# STM32G0C1VET6 register map
File version: 1.0
Registers are 32-bit, access not given, reset 0x0 unless marked. A register's access mark holds for its fields unless they carry their own. Offsets are from the block's base; [hi:lo] are bit positions; {n}, {i} and the like mark numbered series.

## RCC
Base 0x40021000
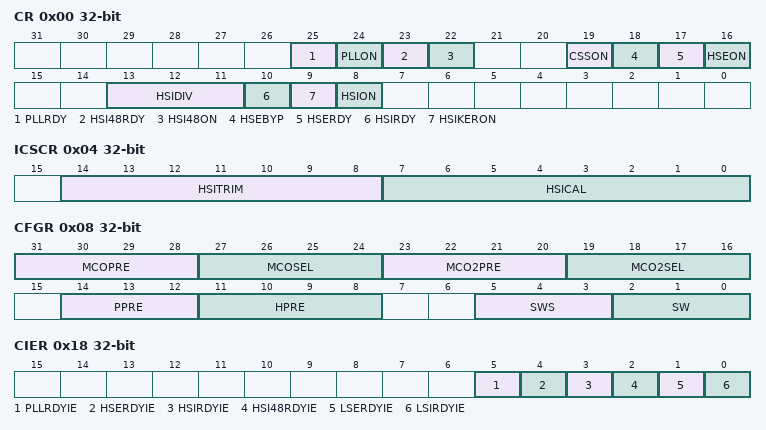
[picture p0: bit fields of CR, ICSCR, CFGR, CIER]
0x00 CR
  [25] PLLRDY, [24] PLLON, [23] HSI48RDY, [22] HSI48ON, [19] CSSON, [18] HSEBYP, [17] HSERDY, [16] HSEON, [13:11] HSIDIV, [10] HSIRDY, [9] HSIKERON, [8] HSION
0x04 ICSCR
  [14:8] HSITRIM, [7:0] HSICAL
0x08 CFGR
  [31:28] MCOPRE, [27:24] MCOSEL, [23:20] MCO2PRE, [19:16] MCO2SEL, [14:12] PPRE, [11:8] HPRE, [5:3] SWS, [2:0] SW
0x0C PLLCFGR
  [31:29] PLLR, [28] PLLREN, [27:25] PLLQ, [24] PLLQEN, [21:17] PLLP, [16] PLLPEN, [14:8] PLLN, [6:4] PLLM, [1] PLLSRC_HSI, [1:0] PLLSRC_HSE
0x14 CRRCR
  [8:0] HSI48CAL
0x18 CIER
  [5] PLLRDYIE, [4] HSERDYIE, [3] HSIRDYIE, [2] HSI48RDYIE, [1] LSERDYIE, [0] LSIRDYIE
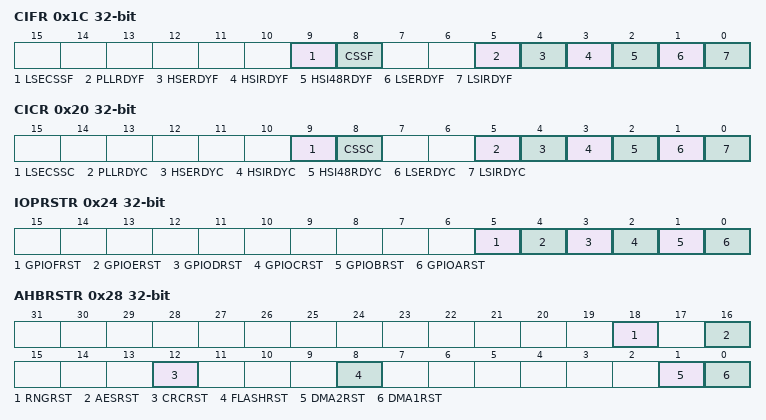
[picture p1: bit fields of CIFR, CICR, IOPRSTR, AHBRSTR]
0x1C CIFR
  [9] LSECSSF, [8] CSSF, [5] PLLRDYF, [4] HSERDYF, [3] HSIRDYF, [2] HSI48RDYF, [1] LSERDYF, [0] LSIRDYF
0x20 CICR
  [9] LSECSSC, [8] CSSC, [5] PLLRDYC, [4] HSERDYC, [3] HSIRDYC, [2] HSI48RDYC, [1] LSERDYC, [0] LSIRDYC
0x24 IOPRSTR
  [5] GPIOFRST, [4] GPIOERST, [3] GPIODRST, [2] GPIOCRST, [1] GPIOBRST, [0] GPIOARST
0x28 AHBRSTR
  [18] RNGRST, [16] AESRST, [12] CRCRST, [8] FLASHRST, [1] DMA2RST, [0] DMA1RST
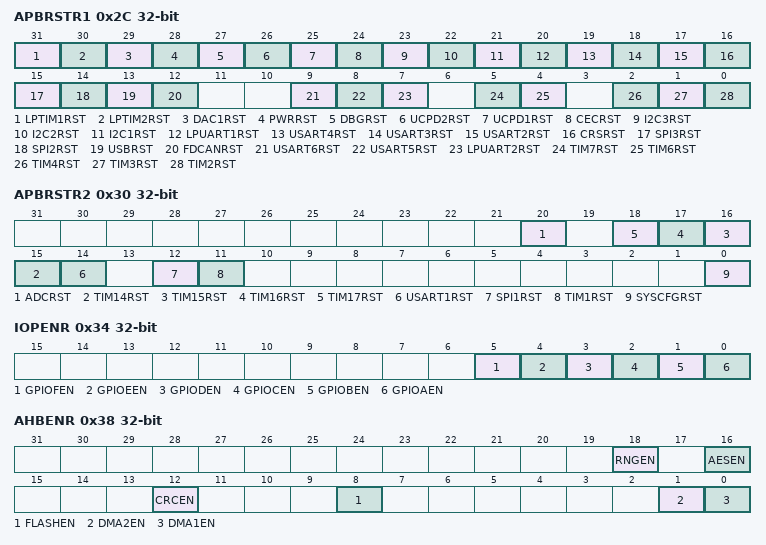
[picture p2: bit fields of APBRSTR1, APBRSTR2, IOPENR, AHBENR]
0x2C APBRSTR1
  [31] LPTIM1RST, [30] LPTIM2RST, [29] DAC1RST, [28] PWRRST, [27] DBGRST, [26] UCPD2RST, [25] UCPD1RST, [24] CECRST, [23] I2C3RST, [22] I2C2RST, [21] I2C1RST, [20] LPUART1RST, [19] USART4RST, [18] USART3RST, [17] USART2RST, [16] CRSRST, [15] SPI3RST, [14] SPI2RST, [13] USBRST, [12] FDCANRST, [9] USART6RST, [8] USART5RST, [7] LPUART2RST, [5] TIM7RST, [4] TIM6RST, [2] TIM4RST, [1] TIM3RST, [0] TIM2RST
0x30 APBRSTR2
  [20] ADCRST, [n+1] TIM{n}RST (n=14..17), [14] USART1RST, [12] SPI1RST, [11] TIM1RST, [0] SYSCFGRST
0x34 IOPENR
  [5] GPIOFEN, [4] GPIOEEN, [3] GPIODEN, [2] GPIOCEN, [1] GPIOBEN, [0] GPIOAEN
0x38 AHBENR
  [18] RNGEN, [16] AESEN, [12] CRCEN, [8] FLASHEN, [1] DMA2EN, [0] DMA1EN
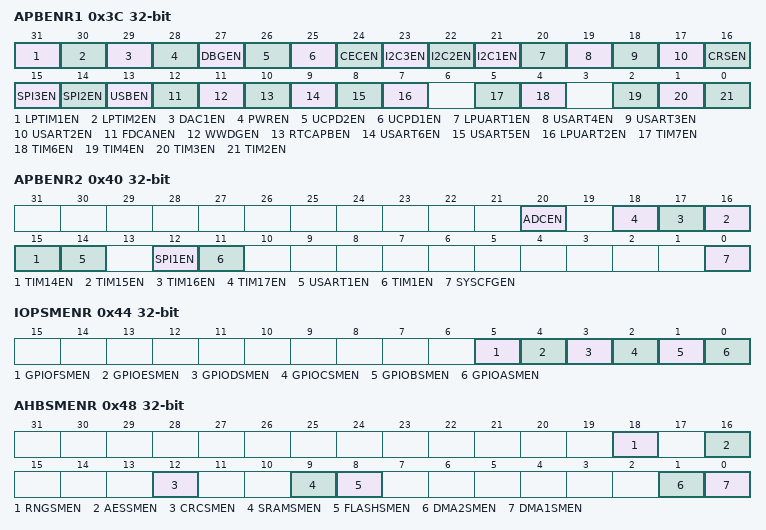
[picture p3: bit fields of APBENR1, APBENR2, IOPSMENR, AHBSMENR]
0x3C APBENR1
  [31] LPTIM1EN, [30] LPTIM2EN, [29] DAC1EN, [28] PWREN, [27] DBGEN, [26] UCPD2EN, [25] UCPD1EN, [24] CECEN, [23] I2C3EN, [22] I2C2EN, [21] I2C1EN, [20] LPUART1EN, [19] USART4EN, [18] USART3EN, [17] USART2EN, [16] CRSEN, [15] SPI3EN, [14] SPI2EN, [13] USBEN, [12] FDCANEN, [11] WWDGEN, [10] RTCAPBEN, [9] USART6EN, [8] USART5EN, [7] LPUART2EN, [5] TIM7EN, [4] TIM6EN, [2] TIM4EN, [1] TIM3EN, [0] TIM2EN
0x40 APBENR2
  [20] ADCEN, [n+1] TIM{n}EN (n=14..17), [14] USART1EN, [12] SPI1EN, [11] TIM1EN, [0] SYSCFGEN
0x44 IOPSMENR
  [5] GPIOFSMEN, [4] GPIOESMEN, [3] GPIODSMEN, [2] GPIOCSMEN, [1] GPIOBSMEN, [0] GPIOASMEN
0x48 AHBSMENR
  [18] RNGSMEN, [16] AESSMEN, [12] CRCSMEN, [9] SRAMSMEN, [8] FLASHSMEN, [1] DMA2SMEN, [0] DMA1SMEN
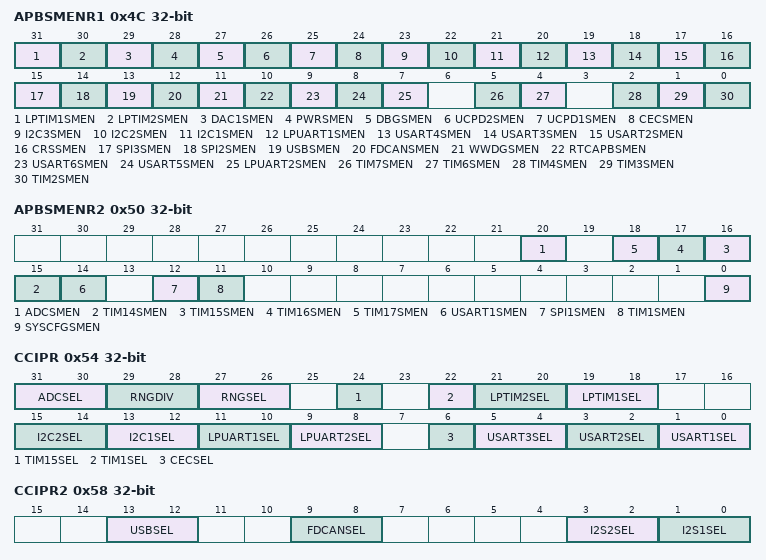
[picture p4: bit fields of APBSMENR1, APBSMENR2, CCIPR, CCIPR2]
0x4C APBSMENR1
  [31] LPTIM1SMEN, [30] LPTIM2SMEN, [29] DAC1SMEN, [28] PWRSMEN, [27] DBGSMEN, [26] UCPD2SMEN, [25] UCPD1SMEN, [24] CECSMEN, [23] I2C3SMEN, [22] I2C2SMEN, [21] I2C1SMEN, [20] LPUART1SMEN, [19] USART4SMEN, [18] USART3SMEN, [17] USART2SMEN, [16] CRSSMEN, [15] SPI3SMEN, [14] SPI2SMEN, [13] USBSMEN, [12] FDCANSMEN, [11] WWDGSMEN, [10] RTCAPBSMEN, [9] USART6SMEN, [8] USART5SMEN, [7] LPUART2SMEN, [5] TIM7SMEN, [4] TIM6SMEN, [2] TIM4SMEN, [1] TIM3SMEN, [0] TIM2SMEN
0x50 APBSMENR2
  [20] ADCSMEN, [n+1] TIM{n}SMEN (n=14..17), [14] USART1SMEN, [12] SPI1SMEN, [11] TIM1SMEN, [0] SYSCFGSMEN
0x54 CCIPR
  [31:30] ADCSEL, [29:28] RNGDIV, [27:26] RNGSEL, [24] TIM15SEL, [22] TIM1SEL, [21:20] LPTIM2SEL, [19:18] LPTIM1SEL, [15:14] I2C2SEL, [13:12] I2C1SEL, [11:10] LPUART1SEL, [9:8] LPUART2SEL, [6] CECSEL, [5:4] USART3SEL, [3:2] USART2SEL, [1:0] USART1SEL
0x58 CCIPR2
  [13:12] USBSEL, [9:8] FDCANSEL, [3:2] I2S2SEL, [1:0] I2S1SEL
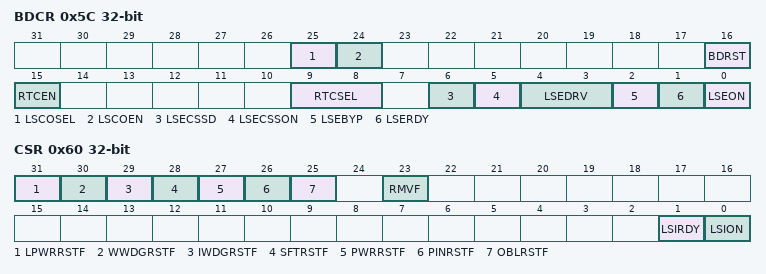
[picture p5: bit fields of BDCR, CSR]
0x5C BDCR
  [25] LSCOSEL, [24] LSCOEN, [16] BDRST, [15] RTCEN, [9:8] RTCSEL, [6] LSECSSD, [5] LSECSSON, [4:3] LSEDRV, [2] LSEBYP, [1] LSERDY, [0] LSEON
0x60 CSR
  [31] LPWRRSTF, [30] WWDGRSTF, [29] IWDGRSTF, [28] SFTRSTF, [27] PWRRSTF, [26] PINRSTF, [25] OBLRSTF, [23] RMVF, [1] LSIRDY, [0] LSION
